# GD32H77x_78x register map
File version: 1.0
CPU: CM7 r1p2, little endian, MPU, FPU, 4 interrupt priority bits
Registers are 32-bit, read-write, reset 0x0 unless marked. A register's access mark holds for its fields unless they carry their own. Offsets are from the block's base; [hi:lo] are bit positions; {n}, {i} and the like mark numbered series.

## MDMA — Master direct memory access controller
Base 0x52000000
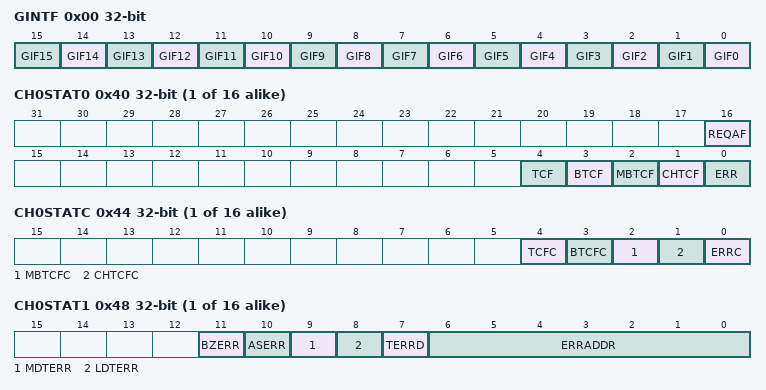
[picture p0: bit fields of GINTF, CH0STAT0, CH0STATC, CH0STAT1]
0x00 GINTF ro — Global interrupt flag register
  [n] GIF{n} (n=0..15) — Global interrupt flag of channel {n}
{0x40+0x40*i} CH{i}STAT0 ro (i=0..15) — Channel {i} status register
  [16] REQAF — Channel x request active flag
  [4] TCF — Channel x buffer transfer complete flag
  [3] BTCF — Channel x block transfer complete flag
  [2] MBTCF — Channel x multi-block transfer complete flag
  [1] CHTCF — Channel x channel transfer complete flag
  [0] ERR — Channel x transfer error flag
{0x44+0x40*i} CH{i}STATC wo (i=0..15) — Channel {i} status clear regist
  [4] TCFC — Channel x buffer transfer complete flag clear
  [3] BTCFC — Channel x buffer block transfer complete flag clear
  [2] MBTCFC — Channel x buffer multi-block transfer complete flag clear
  [1] CHTCFC — Channel x channel transfer complete flag clear
  [0] ERRC — Channel x transfer error flag clear
{0x48+0x40*i} CH{i}STAT1 ro (i=0..15) — Channel {i} status register
  [11] BZERR — Block size error flag
  [10] ASERR — Address and size error flag
  [9] MDTERR — Mask data error flag
  [8] LDTERR — Link data transfer error flag in the last transfer of the channel
  [7] TERRD — Transfer error direction
  [6:0] ERRADDR — Transfer error address
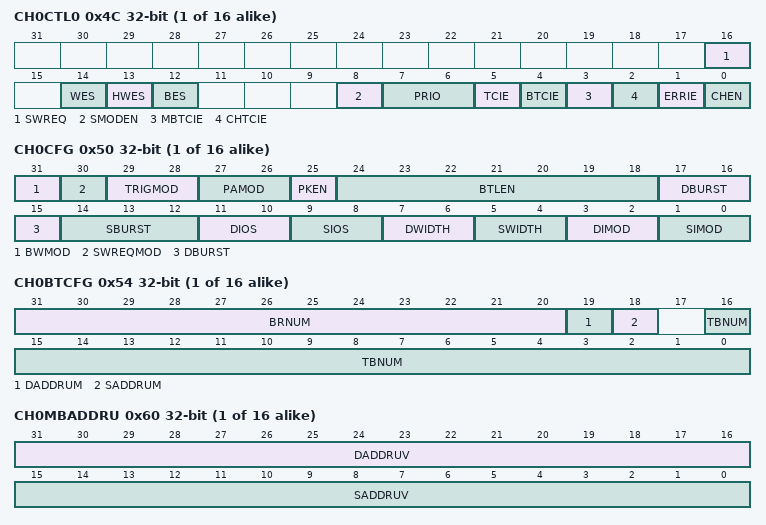
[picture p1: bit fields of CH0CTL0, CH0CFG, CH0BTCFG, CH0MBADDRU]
{0x4C+0x40*i} CH{i}CTL0 access per field (i=0..15) — Channel {i} control register
  [16] SWREQ wo — Software request
  [14] WES rw — Word endianess swapping in double word
  [13] HWES rw — Half word endianess swapping in word
  [12] BES rw — Byte endianess swapping in half word
  [8] SMODEN rw — Secure mode enable
  [7:6] PRIO rw — Priority level
  [5] TCIE rw — Buffer transfer complete interrupt enable
  [4] BTCIE rw — Block transfer complete interrupt enable
  [3] MBTCIE rw — Multi-block transfer complete interrupt enable
  [2] CHTCIE rw — Channel transfer complete interrupt enable
  [1] ERRIE rw — Transfer error interrupt enable
  [0] CHEN rw — Channel enable
{0x50+0x40*i} CH{i}CFG (i=0..15) — Channel {i} configure regist
  [31] BWMOD — Bufferable write mode
  [30] SWREQMOD — Software request mode
  [29:28] TRIGMOD — Trigger mode
  [27:26] PAMOD — Padding and alignement mode
  [25] PKEN — Pack enable
  [24:18] BTLEN — Buffer transfer length
  [17:15] DBURST — Transfer burst type of destination
  [14:12] SBURST — Transfer burst type of source
  [11:10] DIOS — Offset size of destination increment
  [9:8] SIOS — Offset size of source increment
  [7:6] DWIDTH — Data size of destination
  [5:4] SWIDTH — Data size of source
  [3:2] DIMOD — Destination increment mode
  [1:0] SIMOD — Source increment mode
{0x54+0x40*i} CH{i}BTCFG (i=0..15) — Channel {i} block transfer configure regist
  [31:20] BRNUM — Multi-block number
  [19] DADDRUM — Multi-block destination address update mode
  [18] SADDRUM — Multi-block source address update mode
  [16:0] TBNUM — Transfer byte number in block
{0x58+0x40*i} CH{i}SADDR (i=0..15) — Channel {i} source address regist
  [31:0] SADDR — Source address
{0x5C+0x40*i} CH{i}DADDR (i=0..15) — Channel {i} destination address regist
  [31:0] DADDR — Destination address
{0x60+0x40*i} CH{i}MBADDRU (i=0..15) — Channel {i} multi-block address update regist
  [31:16] DADDRUV — Destination address update value
  [15:0] SADDRUV — Source address update value
{0x64+0x40*i} CH{i}LADDR (i=0..15) — Channel {i} link address regist
  [31:0] LADDR — Link address
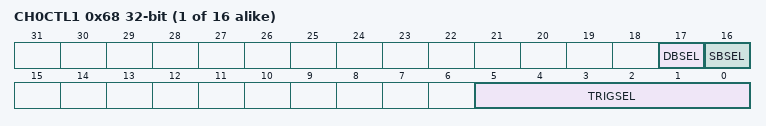
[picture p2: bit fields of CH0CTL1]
{0x68+0x40*i} CH{i}CTL1 (i=0..15) — Channel {i} control register
  [17] DBSEL — Destination bus select
  [16] SBSEL — Source bus select
  [5:0] TRIGSEL — Trigger select
{0x70+0x40*i} CH{i}MADDR (i=0..15) — Channel {i} mask address regist
  [31:0] MADDR — Mask address
{0x74+0x40*i} CH{i}MDATA (i=0..15) — Channel {i} mask data regist
  [31:0] MDATA — Mask data
